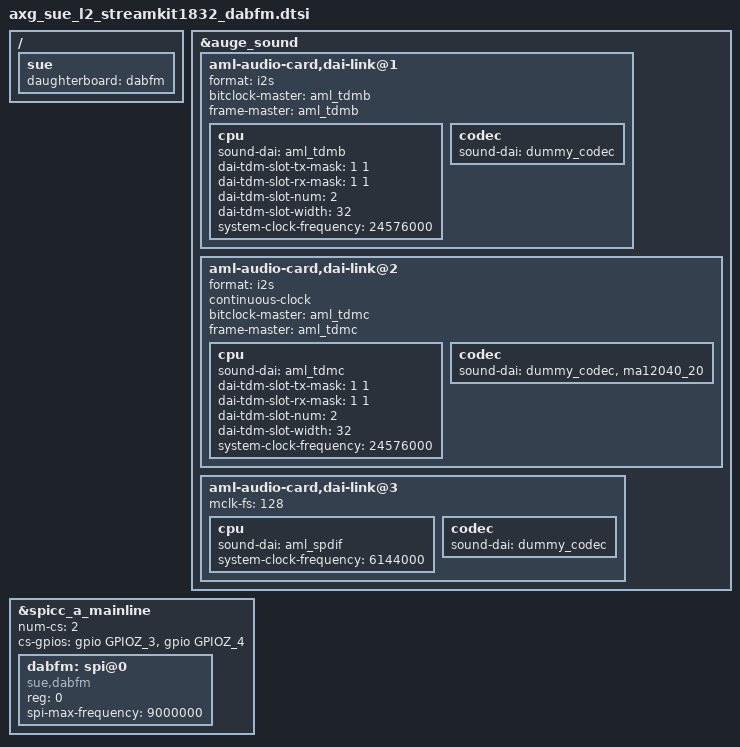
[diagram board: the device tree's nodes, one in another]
/*
 * arch/arm64/boot/dts/amlogic/axg_sue_l2_streamkit1832_dabfm.dtsi
 *
 * Copyright (C) 2020 StreamUnlimited, Inc. All rights reserved.
 *
 * This program is free software; you can redistribute it and/or modify
 * it under the terms of the GNU General Public License as published by
 * the Free Software Foundation; either version 2 of the License, or
 * (at your option) any later version.
 *
 * This program is distributed in the hope that it will be useful, but WITHOUT
 * ANY WARRANTY; without even the implied warranty of MERCHANTABILITY or
 * FITNESS FOR A PARTICULAR PURPOSE.  See the GNU General Public License for
 * more details.
 *
 */

/*
 * DT for components located on StreamKit1832 L0 daughter board which are
 * selected with DIP switches, when the daughter board is present.
 */

/ {
	sue {
		daughterboard = "dabfm";
	};
};

&auge_sound {
	aml-audio-card,dai-link@1 {
		format = "i2s";
		bitclock-master = <&aml_tdmb>;
		frame-master = <&aml_tdmb>;
		cpu {
			sound-dai = <&aml_tdmb>;
			dai-tdm-slot-tx-mask = <1 1>;
			dai-tdm-slot-rx-mask = <1 1>;
			dai-tdm-slot-num = <2>;
			dai-tdm-slot-width = <32>;

			/*
			 * This is the initial MCLK rate on boot.
			 *
			 * NOTE: Since both the TDM-B and the TDM-C are generally running
			 * from the same MCLK, make sure the these entries for the TDM-B
			 * and TDM-C links match.
			 */
			system-clock-frequency = <24576000>;
		};
		codec {
			sound-dai = <&dummy_codec>;
		};
	};

	aml-audio-card,dai-link@2 {
		format = "i2s";
		continuous-clock;
		bitclock-master = <&aml_tdmc>;
		frame-master = <&aml_tdmc>;
		cpu {
			sound-dai = <&aml_tdmc>;
			dai-tdm-slot-tx-mask = <1 1>;
			dai-tdm-slot-rx-mask = <1 1>;
			dai-tdm-slot-num = <2>;
			dai-tdm-slot-width = <32>;
			system-clock-frequency = <24576000>;
		};
		codec {
			/*
			 * Linux does not list the MA12040 amplifier as a
			 * device, because it have incomplete DAI properties,
			 * because it is not an actual codec, only an analogue
			 * playback device.
			 * It is therefor important to set this driver as a
			 * multi codec device in the device tree e.g
			 * sound-dai = <&dummy_codec &ma12040_20>; Linux will
			 * list the sound dai if one of the codecs have
			 * sufficient DAI parameters.
			 * This corresponds to the actual configuration on
			 * streamkit1832:
			 *   Stream1832 => bootstrapped AK4430ET => MA12040
			 */
			sound-dai = <&dummy_codec &ma12040_20>;
		};
	};

	aml-audio-card,dai-link@3 {
		mclk-fs = <128>;
		cpu {
			sound-dai = <&aml_spdif>;
			system-clock-frequency = <6144000>;
		};
		codec {
			sound-dai = <&dummy_codec>;
		};
	};
};

&spicc_a_mainline {
	num-cs = <2>;
	cs-gpios = <&gpio GPIOZ_3 GPIO_ACTIVE_HIGH>,
			<&gpio GPIOZ_4 GPIO_ACTIVE_HIGH>;

	dabfm: spi@0 {
		compatible = "sue,dabfm";
		status = "okay";
		reg = <0>;
		spi-max-frequency = <9000000>;
	};
};
